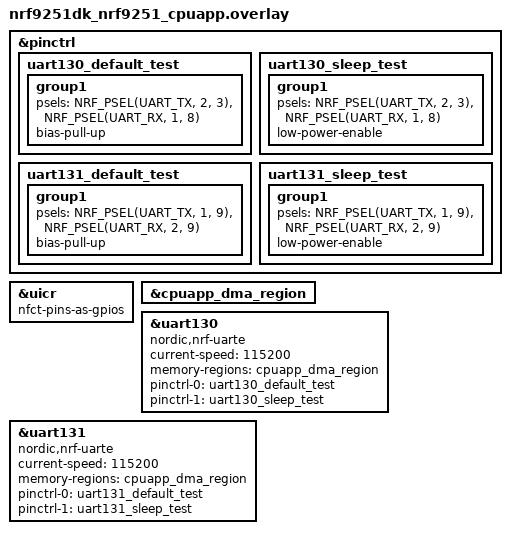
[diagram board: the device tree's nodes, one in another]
/*
 * Copyright (c) 2026 Nordic Semiconductor ASA
 *
 * SPDX-License-Identifier: LicenseRef-Nordic-5-Clause
 */

/*
 * Required loopbacks:
 * P1.08 <-> P1.09 (connected with NFCT antena)
 * P2.03 <-> P2.09
 */

&pinctrl {
	uart130_default_test: uart130_default_test {
		group1 {
			psels = <NRF_PSEL(UART_TX, 2, 3)>,
				<NRF_PSEL(UART_RX, 1, 8)>;
			bias-pull-up;
		};
	};

	uart130_sleep_test: uart130_sleep_test {
		group1 {
			psels = <NRF_PSEL(UART_TX, 2, 3)>,
				<NRF_PSEL(UART_RX, 1, 8)>;
			low-power-enable;
		};
	};

	uart131_default_test: uart131_default_test {
		group1 {
			psels = <NRF_PSEL(UART_TX, 1, 9)>,
				<NRF_PSEL(UART_RX, 2, 9)>;
			bias-pull-up;
		};
	};

	uart131_sleep_test: uart131_sleep_test {
		group1 {
			psels = <NRF_PSEL(UART_TX, 1, 9)>,
				<NRF_PSEL(UART_RX, 2, 9)>;
			low-power-enable;
		};
	};
};

&uicr {
	nfct-pins-as-gpios;
};

&cpuapp_dma_region {
	status = "okay";
};

dut_uart_a: &uart130 {
	compatible = "nordic,nrf-uarte";
	current-speed = <115200>;
	status = "okay";
	memory-regions = <&cpuapp_dma_region>;
	pinctrl-0 = <&uart130_default_test>;
	pinctrl-1 = <&uart130_sleep_test>;
	pinctrl-names = "default", "sleep";
	/delete-property/ hw-flow-control;
};

dut_uart_b: &uart131 {
	compatible = "nordic,nrf-uarte";
	current-speed = <115200>;
	status = "okay";
	memory-regions = <&cpuapp_dma_region>;
	pinctrl-0 = <&uart131_default_test>;
	pinctrl-1 = <&uart131_sleep_test>;
	pinctrl-names = "default", "sleep";
	/delete-property/ hw-flow-control;
};
